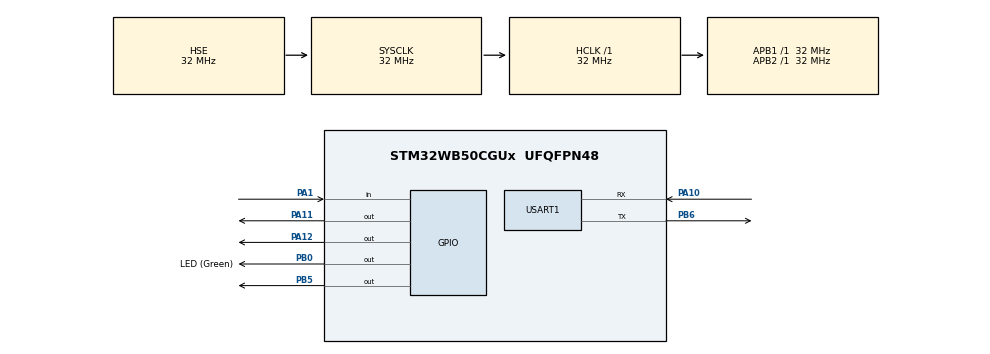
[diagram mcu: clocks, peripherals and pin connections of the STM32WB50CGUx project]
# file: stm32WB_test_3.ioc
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Dma.Request0=USART1_RX
Dma.Request1=USART1_TX
Dma.USART1_RX.0.Direction=DMA_PERIPH_TO_MEMORY
Dma.USART1_RX.0.EventEnable=DISABLE
Dma.USART1_RX.0.Instance=DMA1_Channel1
Dma.USART1_RX.0.MemDataAlignment=DMA_MDATAALIGN_BYTE
Dma.USART1_RX.0.MemInc=DMA_MINC_ENABLE
Dma.USART1_RX.0.Mode=DMA_NORMAL
Dma.USART1_RX.0.PeriphDataAlignment=DMA_PDATAALIGN_BYTE
Dma.USART1_RX.0.PeriphInc=DMA_PINC_DISABLE
Dma.USART1_RX.0.Polarity=HAL_DMAMUX_REQ_GEN_RISING
Dma.USART1_RX.0.Priority=DMA_PRIORITY_LOW
Dma.USART1_RX.0.RequestNumber=1
Dma.USART1_RX.0.SignalID=NONE
Dma.USART1_RX.0.SyncEnable=DISABLE
Dma.USART1_RX.0.SyncPolarity=HAL_DMAMUX_SYNC_NO_EVENT
Dma.USART1_RX.0.SyncRequestNumber=1
Dma.USART1_RX.0.SyncSignalID=NONE
Dma.USART1_TX.1.Direction=DMA_MEMORY_TO_PERIPH
Dma.USART1_TX.1.EventEnable=DISABLE
Dma.USART1_TX.1.Instance=DMA1_Channel2
Dma.USART1_TX.1.MemDataAlignment=DMA_MDATAALIGN_BYTE
Dma.USART1_TX.1.MemInc=DMA_MINC_ENABLE
Dma.USART1_TX.1.Mode=DMA_NORMAL
Dma.USART1_TX.1.PeriphDataAlignment=DMA_PDATAALIGN_BYTE
Dma.USART1_TX.1.PeriphInc=DMA_PINC_DISABLE
Dma.USART1_TX.1.Polarity=HAL_DMAMUX_REQ_GEN_RISING
Dma.USART1_TX.1.Priority=DMA_PRIORITY_LOW
Dma.USART1_TX.1.RequestNumber=1
Dma.USART1_TX.1.SignalID=NONE
Dma.USART1_TX.1.SyncEnable=DISABLE
Dma.USART1_TX.1.SyncPolarity=HAL_DMAMUX_SYNC_NO_EVENT
Dma.USART1_TX.1.SyncRequestNumber=1
Dma.USART1_TX.1.SyncSignalID=NONE
Mcu.Family=STM32WB
Mcu.Name=STM32WB50CGUx
Mcu.Package=UFQFPN48
NVIC.DMA1_Channel1_IRQn=true\:0\:0\:false\:false\:true\:false\:true
NVIC.DMA1_Channel2_IRQn=true\:0\:0\:false\:false\:true\:false\:true
NVIC.HSEM_IRQn=true\:0\:0\:false\:false\:true\:false\:true
NVIC.PriorityGroup=NVIC_PRIORITYGROUP_4
NVIC.USART1_IRQn=true\:0\:0\:false\:false\:true\:true\:true
OSC_IN.Mode=HSE-External-Oscillator
OSC_IN.Signal=RCC_OSC_IN
OSC_OUT.Mode=HSE-External-Oscillator
OSC_OUT.Signal=RCC_OSC_OUT
PA1.Signal=GPIO_Input
PA10.Mode=Asynchronous
PA10.Signal=USART1_RX
PA11.Signal=GPIO_Output
PA12.Signal=GPIO_Output
PA13.Mode=Serial_Wire
PA13.Signal=SYS_JTMS-SWDIO
PA14.Mode=Serial_Wire
PA14.Signal=SYS_JTCK-SWCLK
PB0.GPIO_Label=LED (Green)
PB0.Signal=GPIO_Output
PB5.Signal=GPIO_Output
PB6.Mode=Asynchronous
PB6.Signal=USART1_TX
PC14-OSC32_IN.Mode=LSE-External-Oscillator
PC14-OSC32_IN.Signal=RCC_OSC32_IN
PC15-OSC32_OUT.Mode=LSE-External-Oscillator
PC15-OSC32_OUT.Signal=RCC_OSC32_OUT
ProjectManager.HeapSize=0x200
ProjectManager.StackSize=0x400
ProjectManager.TargetToolchain=STM32CubeIDE
RCC.ADCFreq_Value=32000000
RCC.AHBFreq_Value=32000000
RCC.APB1Freq_Value=32000000
RCC.APB1TimFreq_Value=32000000
RCC.APB2Freq_Value=32000000
RCC.APB2TimFreq_Value=32000000
RCC.APB3Freq_Value=16000000
RCC.CortexFreq_Value=32000000
RCC.HCLKFreq_Value=32000000
RCC.HSE_VALUE=32000000
RCC.HSI48_VALUE=48000000
RCC.HSI_VALUE=16000000
RCC.MSIClockRange=RCC_MSIRANGE_10
RCC.RFWKPClockSelection=RCC_RFWKPCLKSOURCE_LSE
RCC.RTCClockSelection=RCC_RTCCLKSOURCE_LSE
RCC.SYSCLKFreq_VALUE=32000000
RCC.SYSCLKSource=RCC_SYSCLKSOURCE_HSE
RCC.VCOOutputFreq_Value=256000000
RF1.Mode=RF1_Activate
RF1.Signal=RF_RF1
STM32_WPAN.AD_TYPE_APPEARANCE=0x01, 0x80 /* GENERIC_REMOTE_CONTOL_APPEARANCE */
STM32_WPAN.AD_TYPE_COMPLETE_LOCAL_NAME=hukam
STM32_WPAN.AD_TYPE_COMPLETE_LOCAL_NAME_LENGTH=6
STM32_WPAN.AD_TYPE_LE_ROLE=0x04 /* Peripheral and Central Role supported but Peripheral Role preferred for connection establishment */
STM32_WPAN.AD_TYPE_MANUFACTURER_SPECIFIC_DATA_COMPANY_IDENTIFIER=00,00
STM32_WPAN.BLE_APPLICATION_TYPE=BLE_SERVER_PROFILE
STM32_WPAN.BLE_DBG_APP_EN=0
STM32_WPAN.CFG_CONSOLE_MENU=hw_uart1
STM32_WPAN.CFG_GAP_DEVICE_NAME=hukamTech
STM32_WPAN.CFG_HW_RESET_BY_FW=0
STM32_WPAN.CFG_HW_USART1_DMA_TX_SUPPORTED=1
STM32_WPAN.CFG_HW_USART1_ENABLED=1
STM32_WPAN.CFG_LPM_SUPPORTED=1
STM32_WPAN.CFG_UART_GUI=hw_uart1
STM32_WPAN.GAP_PERIPHERAL_ROLE=1
STM32_WPAN.INCLUDE_AD_TYPE_128_BIT_SERV_UUID_CMPLT_LIST=0
STM32_WPAN.INCLUDE_AD_TYPE_APPEARANCE=1
STM32_WPAN.INCLUDE_AD_TYPE_COMPLETE_LOCAL_NAME=1
STM32_WPAN.INCLUDE_AD_TYPE_LE_ROLE=1
STM32_WPAN.INCLUDE_AD_TYPE_MANUFACTURER_SPECIFIC_DATA=0
STM32_WPAN.INCLUDE_AD_TYPE_SHORTENED_LOCAL_NAME=0
STM32_WPAN.LOCAL_NAME=check1
STM32_WPAN.LOCAL_NAME_FORMATTED=,'c','h','e','c','k','1'
STM32_WPAN.NUMBER_OF_SERVICES=2
STM32_WPAN.SERVICE1_CHAR1_ATTR_PERMISSION_AUTHEN_READ=ATTR_PERMISSION_AUTHEN_READ
STM32_WPAN.SERVICE1_CHAR1_ATTR_PERMISSION_AUTHOR_READ=ATTR_PERMISSION_AUTHOR_READ
STM32_WPAN.SERVICE1_CHAR1_ATTR_PERMISSION_ENCRY_READ=ATTR_PERMISSION_ENCRY_READ
STM32_WPAN.SERVICE1_CHAR1_GATT_NOTIFY_ATTRIBUTE_WRITE=\ 
STM32_WPAN.SERVICE1_CHAR1_GATT_NOTIFY_WRITE_REQ_AND_WAIT_FOR_APPL_RESP=\ 
STM32_WPAN.SERVICE1_CHAR1_LONG_NAME=sw_no
STM32_WPAN.SERVICE1_CHAR1_PROP_BROADCAST=\ 
STM32_WPAN.SERVICE1_CHAR1_PROP_NOTIFY=CHAR_PROP_NOTIFY
STM32_WPAN.SERVICE1_CHAR1_PROP_READ=CHAR_PROP_READ
STM32_WPAN.SERVICE1_CHAR1_SHORT_NAME=sw_no
STM32_WPAN.SERVICE1_CHAR2_ATTR_PERMISSION_AUTHEN_READ=ATTR_PERMISSION_AUTHEN_READ
STM32_WPAN.SERVICE1_CHAR2_ATTR_PERMISSION_AUTHEN_WRITE=ATTR_PERMISSION_AUTHEN_WRITE
STM32_WPAN.SERVICE1_CHAR2_ATTR_PERMISSION_AUTHOR_READ=ATTR_PERMISSION_AUTHOR_READ
STM32_WPAN.SERVICE1_CHAR2_ATTR_PERMISSION_AUTHOR_WRITE=ATTR_PERMISSION_AUTHOR_WRITE
STM32_WPAN.SERVICE1_CHAR2_ATTR_PERMISSION_ENCRY_READ=ATTR_PERMISSION_ENCRY_READ
STM32_WPAN.SERVICE1_CHAR2_ATTR_PERMISSION_ENCRY_WRITE=ATTR_PERMISSION_ENCRY_WRITE
STM32_WPAN.SERVICE1_CHAR2_GATT_NOTIFY_READ_REQ_AND_WAIT_FOR_APPL_RESP=\ 
STM32_WPAN.SERVICE1_CHAR2_GATT_NOTIFY_WRITE_REQ_AND_WAIT_FOR_APPL_RESP=\ 
STM32_WPAN.SERVICE1_CHAR2_LONG_NAME=update_sw
STM32_WPAN.SERVICE1_CHAR2_PROP_BROADCAST=\ 
STM32_WPAN.SERVICE1_CHAR2_PROP_INDICATE=CHAR_PROP_INDICATE
STM32_WPAN.SERVICE1_CHAR2_PROP_NOTIFY=CHAR_PROP_NOTIFY
STM32_WPAN.SERVICE1_CHAR2_PROP_READ=CHAR_PROP_READ
STM32_WPAN.SERVICE1_CHAR2_PROP_WRITE=CHAR_PROP_WRITE
STM32_WPAN.SERVICE1_CHAR2_SHORT_NAME=update_sw
STM32_WPAN.SERVICE1_LONG_NAME=sw_status
STM32_WPAN.SERVICE1_NUMBER_OF_CHARACTERISTICS=1
STM32_WPAN.SERVICE1_SHORT_NAME=sw_status
STM32_WPAN.SERVICE2_CHAR1_ATTR_PERMISSION_AUTHEN_READ=ATTR_PERMISSION_AUTHEN_READ
STM32_WPAN.SERVICE2_CHAR1_ATTR_PERMISSION_AUTHEN_WRITE=ATTR_PERMISSION_AUTHEN_WRITE
STM32_WPAN.SERVICE2_CHAR1_ATTR_PERMISSION_AUTHOR_READ=ATTR_PERMISSION_AUTHOR_READ
STM32_WPAN.SERVICE2_CHAR1_ATTR_PERMISSION_AUTHOR_WRITE=ATTR_PERMISSION_AUTHOR_WRITE
STM32_WPAN.SERVICE2_CHAR1_ATTR_PERMISSION_ENCRY_READ=ATTR_PERMISSION_ENCRY_READ
STM32_WPAN.SERVICE2_CHAR1_ATTR_PERMISSION_ENCRY_WRITE=ATTR_PERMISSION_ENCRY_WRITE
STM32_WPAN.SERVICE2_CHAR1_GATT_NOTIFY_READ_REQ_AND_WAIT_FOR_APPL_RESP=\ 
STM32_WPAN.SERVICE2_CHAR1_LONG_NAME=pin_no
STM32_WPAN.SERVICE2_CHAR1_PROP_BROADCAST=\ 
STM32_WPAN.SERVICE2_CHAR1_PROP_INDICATE=CHAR_PROP_INDICATE
STM32_WPAN.SERVICE2_CHAR1_PROP_NOTIFY=CHAR_PROP_NOTIFY
STM32_WPAN.SERVICE2_CHAR1_PROP_READ=CHAR_PROP_READ
STM32_WPAN.SERVICE2_CHAR1_PROP_WRITE=CHAR_PROP_WRITE
STM32_WPAN.SERVICE2_CHAR1_SHORT_NAME=pin_no
STM32_WPAN.SERVICE2_LONG_NAME=update_sw
STM32_WPAN.SERVICE2_SHORT_NAME=update_sw
USART1.VirtualMode-Asynchronous=VM_ASYNC
VP_HSEM_VS_HSEM.Mode=HSEM_Activate
VP_RTC_VS_RTC_Activate.Mode=RTC_Enabled
VP_SEQUENCER_VS_SEQUENCER.Mode=SEQUENCER_Enabled
VP_STM32_WPAN_VS_BLE_HOST.Mode=STM32_WPAN_Enabled
VP_TINY_LPM_VS_TINY_LPM.Mode=TINY_LPM_Enabled
board=custom

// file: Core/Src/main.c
/* USER CODE BEGIN Header */
/**
  ******************************************************************************
  * @file           : main.c
  * @brief          : Main program body
  ******************************************************************************
  * @attention
  *
  * <h2><center>&copy; Copyright (c) 2021 STMicroelectronics.
  * All rights reserved.</center></h2>
  *
  * This software component is licensed by ST under BSD 3-Clause license,
  * the "License"; You may not use this file except in compliance with the
  * License. You may obtain a copy of the License at:
  *                        opensource.org/licenses/BSD-3-Clause
  *
  ******************************************************************************
  */
/* USER CODE END Header */
#include "main.h"
#include "app_entry.h"
#include "app_common.h"

/* USER CODE BEGIN Includes */
#include "stm32_seq.h"
/* USER CODE END Includes */

RTC_HandleTypeDef hrtc;

UART_HandleTypeDef huart1;
DMA_HandleTypeDef hdma_usart1_rx;
DMA_HandleTypeDef hdma_usart1_tx;

void SystemClock_Config(void);
static void MX_GPIO_Init(void);
static void MX_DMA_Init(void);
static void MX_RF_Init(void);
static void MX_RTC_Init(void);
static void MX_USART1_UART_Init(void);

int main(void)
{

  /* MCU Configuration--------------------------------------------------------*/

  /* Reset of all peripherals, Initializes the Flash interface and the Systick. */
  HAL_Init();

  /* Configure the system clock */
  SystemClock_Config();

  /* Initialize all configured peripherals */
  MX_GPIO_Init();
  MX_DMA_Init();
  MX_RF_Init();
  MX_RTC_Init();
  MX_USART1_UART_Init();

  /* Init code for STM32_WPAN */
  APPE_Init();
  /* Infinite loop */
  while (1)
  {

    /* USER CODE BEGIN 3 */
	  UTIL_SEQ_Run(~0);

	  HAL_GPIO_TogglePin (GPIOA, GPIO_PIN_0);
	  HAL_GPIO_TogglePin (GPIOA, GPIO_PIN_1);

	  HAL_Delay(1000);
	//  aci_gap_set_non_connectable();
  }
  /* USER CODE END 3 */
}

void SystemClock_Config(void)
{
  RCC_OscInitTypeDef RCC_OscInitStruct = {0};
  RCC_ClkInitTypeDef RCC_ClkInitStruct = {0};
  RCC_PeriphCLKInitTypeDef PeriphClkInitStruct = {0};

  /** Configure LSE Drive Capability
  */
  HAL_PWR_EnableBkUpAccess();
  __HAL_RCC_LSEDRIVE_CONFIG(RCC_LSEDRIVE_LOW);
  /** Initializes the RCC Oscillators according to the specified parameters
  * in the RCC_OscInitTypeDef structure.
  */
  RCC_OscInitStruct.OscillatorType = RCC_OSCILLATORTYPE_HSI|RCC_OSCILLATORTYPE_HSE
                              |RCC_OSCILLATORTYPE_LSE;
  RCC_OscInitStruct.HSEState = RCC_HSE_ON;
  RCC_OscInitStruct.LSEState = RCC_LSE_ON;
  RCC_OscInitStruct.HSIState = RCC_HSI_ON;
  RCC_OscInitStruct.HSICalibrationValue = RCC_HSICALIBRATION_DEFAULT;
  RCC_OscInitStruct.PLL.PLLState = RCC_PLL_NONE;
  if (HAL_RCC_OscConfig(&RCC_OscInitStruct) != HAL_OK)
  {
    Error_Handler();
  }
  /** Configure the SYSCLKSource, HCLK, PCLK1 and PCLK2 clocks dividers
  */
  RCC_ClkInitStruct.ClockType = RCC_CLOCKTYPE_HCLK4|RCC_CLOCKTYPE_HCLK2
                              |RCC_CLOCKTYPE_HCLK|RCC_CLOCKTYPE_SYSCLK
                              |RCC_CLOCKTYPE_PCLK1|RCC_CLOCKTYPE_PCLK2;
  RCC_ClkInitStruct.SYSCLKSource = RCC_SYSCLKSOURCE_HSE;
  RCC_ClkInitStruct.AHBCLKDivider = RCC_SYSCLK_DIV1;
  RCC_ClkInitStruct.APB1CLKDivider = RCC_HCLK_DIV1;
  RCC_ClkInitStruct.APB2CLKDivider = RCC_HCLK_DIV1;
  RCC_ClkInitStruct.AHBCLK2Divider = RCC_SYSCLK_DIV1;
  RCC_ClkInitStruct.AHBCLK4Divider = RCC_SYSCLK_DIV1;

  if (HAL_RCC_ClockConfig(&RCC_ClkInitStruct, FLASH_LATENCY_3) != HAL_OK)
  {
    Error_Handler();
  }
  /** Initializes the peripherals clocks
  */
  PeriphClkInitStruct.PeriphClockSelection = RCC_PERIPHCLK_RFWAKEUP|RCC_PERIPHCLK_RTC
                              |RCC_PERIPHCLK_USART1;
  PeriphClkInitStruct.Usart1ClockSelection = RCC_USART1CLKSOURCE_PCLK2;
  PeriphClkInitStruct.RTCClockSelection = RCC_RTCCLKSOURCE_LSE;
  PeriphClkInitStruct.RFWakeUpClockSelection = RCC_RFWKPCLKSOURCE_LSE;
  if (HAL_RCCEx_PeriphCLKConfig(&PeriphClkInitStruct) != HAL_OK)
  {
    Error_Handler();
  }
}

static void MX_RF_Init(void)
{

}

static void MX_RTC_Init(void)
{

  /** Initialize RTC Only
  */
  hrtc.Instance = RTC;
  hrtc.Init.HourFormat = RTC_HOURFORMAT_24;
  hrtc.Init.AsynchPrediv = CFG_RTC_ASYNCH_PRESCALER;
  hrtc.Init.SynchPrediv = CFG_RTC_SYNCH_PRESCALER;
  hrtc.Init.OutPut = RTC_OUTPUT_DISABLE;
  hrtc.Init.OutPutPolarity = RTC_OUTPUT_POLARITY_HIGH;
  hrtc.Init.OutPutType = RTC_OUTPUT_TYPE_OPENDRAIN;
  hrtc.Init.OutPutRemap = RTC_OUTPUT_REMAP_NONE;
  if (HAL_RTC_Init(&hrtc) != HAL_OK)
  {
    Error_Handler();
  }

}

static void MX_USART1_UART_Init(void)
{

  huart1.Instance = USART1;
  huart1.Init.BaudRate = 115200;
  huart1.Init.WordLength = UART_WORDLENGTH_8B;
  huart1.Init.StopBits = UART_STOPBITS_1;
  huart1.Init.Parity = UART_PARITY_NONE;
  huart1.Init.Mode = UART_MODE_TX_RX;
  huart1.Init.HwFlowCtl = UART_HWCONTROL_NONE;
  huart1.Init.OverSampling = UART_OVERSAMPLING_8;
  huart1.Init.OneBitSampling = UART_ONE_BIT_SAMPLE_DISABLE;
  huart1.Init.ClockPrescaler = UART_PRESCALER_DIV1;
  huart1.AdvancedInit.AdvFeatureInit = UART_ADVFEATURE_NO_INIT;
  if (HAL_UART_Init(&huart1) != HAL_OK)
  {
    Error_Handler();
  }
  if (HAL_UARTEx_SetTxFifoThreshold(&huart1, UART_TXFIFO_THRESHOLD_1_8) != HAL_OK)
  {
    Error_Handler();
  }
  if (HAL_UARTEx_SetRxFifoThreshold(&huart1, UART_RXFIFO_THRESHOLD_1_8) != HAL_OK)
  {
    Error_Handler();
  }
  if (HAL_UARTEx_DisableFifoMode(&huart1) != HAL_OK)
  {
    Error_Handler();
  }

}

static void MX_DMA_Init(void)
{

  /* DMA controller clock enable */
  __HAL_RCC_DMAMUX1_CLK_ENABLE();
  __HAL_RCC_DMA1_CLK_ENABLE();

  /* DMA interrupt init */
  /* DMA1_Channel1_IRQn interrupt configuration */
  HAL_NVIC_SetPriority(DMA1_Channel1_IRQn, 0, 0);
  HAL_NVIC_EnableIRQ(DMA1_Channel1_IRQn);
  /* DMA1_Channel2_IRQn interrupt configuration */
  HAL_NVIC_SetPriority(DMA1_Channel2_IRQn, 0, 0);
  HAL_NVIC_EnableIRQ(DMA1_Channel2_IRQn);

}

static void MX_GPIO_Init(void)
{
  GPIO_InitTypeDef GPIO_InitStruct = {0};

  /* GPIO Ports Clock Enable */
  __HAL_RCC_GPIOC_CLK_ENABLE();
  __HAL_RCC_GPIOA_CLK_ENABLE();
  __HAL_RCC_GPIOB_CLK_ENABLE();

  /*Configure GPIO pin Output Level */
  HAL_GPIO_WritePin(GPIOB, LED_Pin|GPIO_PIN_5, GPIO_PIN_RESET);

  /*Configure GPIO pin Output Level */
  HAL_GPIO_WritePin(GPIOA, GPIO_PIN_11|GPIO_PIN_12, GPIO_PIN_RESET);

  /*Configure GPIO pin : PA1 */
  GPIO_InitStruct.Pin = GPIO_PIN_1;
  GPIO_InitStruct.Mode = GPIO_MODE_INPUT;
  GPIO_InitStruct.Pull = GPIO_NOPULL;
  HAL_GPIO_Init(GPIOA, &GPIO_InitStruct);

  /*Configure GPIO pins : LED_Pin PB5 */
  GPIO_InitStruct.Pin = LED_Pin|GPIO_PIN_5;
  GPIO_InitStruct.Mode = GPIO_MODE_OUTPUT_PP;
  GPIO_InitStruct.Pull = GPIO_NOPULL;
  GPIO_InitStruct.Speed = GPIO_SPEED_FREQ_LOW;
  HAL_GPIO_Init(GPIOB, &GPIO_InitStruct);

  /*Configure GPIO pins : PA11 PA12 */
  GPIO_InitStruct.Pin = GPIO_PIN_11|GPIO_PIN_12;
  GPIO_InitStruct.Mode = GPIO_MODE_OUTPUT_PP;
  GPIO_InitStruct.Pull = GPIO_NOPULL;
  GPIO_InitStruct.Speed = GPIO_SPEED_FREQ_LOW;
  HAL_GPIO_Init(GPIOA, &GPIO_InitStruct);

}

void Error_Handler(void)
{
}

/************************ (C) COPYRIGHT STMicroelectronics *****END OF FILE****/
